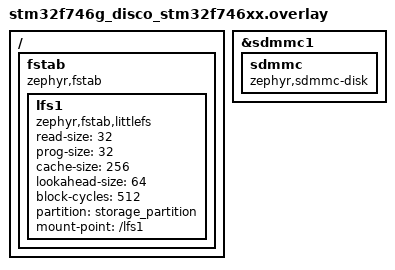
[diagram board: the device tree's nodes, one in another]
/*
 * Copyright (c) 2024 STMicroelectronics
 *
 * SPDX-License-Identifier: Apache-2.0
 */

&sdmmc1 {
        sdmmc {
		compatible = "zephyr,sdmmc-disk";
	};
};

/ {
	fstab {
		compatible = "zephyr,fstab";
		lfs1: lfs1 {
			compatible = "zephyr,fstab,littlefs";
			read-size = <32>;
			prog-size = <32>;
			cache-size = <256>;
			lookahead-size = <64>;
			block-cycles = <512>;
			partition = <&storage_partition>;
			mount-point = "/lfs1";
		};
	};
};
